VERSION ""

NS_ :

BS_:

BU_:

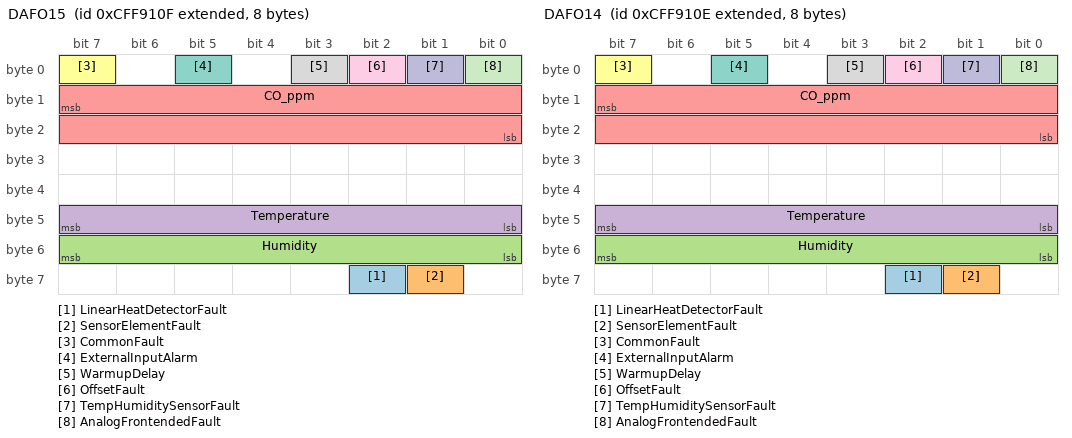
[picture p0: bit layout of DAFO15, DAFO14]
BO_ 2365559055 DAFO15: 8 Vector__XXX
 SG_ LinearHeatDetectorFault : 58|1@1+ (1,0) [0|0] "" Vector__XXX
 SG_ SensorElementFault : 57|1@1+ (1,0) [0|0] "" Vector__XXX
 SG_ Humidity : 48|8@1+ (1,0) [0|100] "" Vector__XXX
 SG_ Temperature : 40|8@1+ (1,0) [-40|125] "" Vector__XXX
 SG_ CO_ppm : 15|16@0+ (1,0) [0|0] "" Vector__XXX
 SG_ CommonFault : 7|1@1+ (1,0) [0|0] "" Vector__XXX
 SG_ ExternalInputAlarm : 5|1@1+ (1,0) [0|1] "" Vector__XXX
 SG_ WarmupDelay : 3|1@1+ (1,0) [0|0] "" Vector__XXX
 SG_ OffsetFault : 2|1@1+ (1,0) [0|0] "" Vector__XXX
 SG_ TempHumiditySensorFault : 1|1@1+ (1,0) [0|0] "" Vector__XXX
 SG_ AnalogFrontendedFault : 0|1@1+ (1,0) [0|1] "" Vector__XXX

BO_ 2365559054 DAFO14: 8 Vector__XXX
 SG_ LinearHeatDetectorFault : 58|1@1+ (1,0) [0|0] "" Vector__XXX
 SG_ SensorElementFault : 57|1@1+ (1,0) [0|0] "" Vector__XXX
 SG_ Humidity : 48|8@1+ (1,0) [0|100] "" Vector__XXX
 SG_ Temperature : 40|8@1+ (1,0) [-40|125] "" Vector__XXX
 SG_ CO_ppm : 15|16@0+ (1,0) [0|0] "" Vector__XXX
 SG_ CommonFault : 7|1@1+ (1,0) [0|0] "" Vector__XXX
 SG_ ExternalInputAlarm : 5|1@1+ (1,0) [0|1] "" Vector__XXX
 SG_ WarmupDelay : 3|1@1+ (1,0) [0|0] "" Vector__XXX
 SG_ OffsetFault : 2|1@1+ (1,0) [0|0] "" Vector__XXX
 SG_ TempHumiditySensorFault : 1|1@1+ (1,0) [0|0] "" Vector__XXX
 SG_ AnalogFrontendedFault : 0|1@1+ (1,0) [0|1] "" Vector__XXX

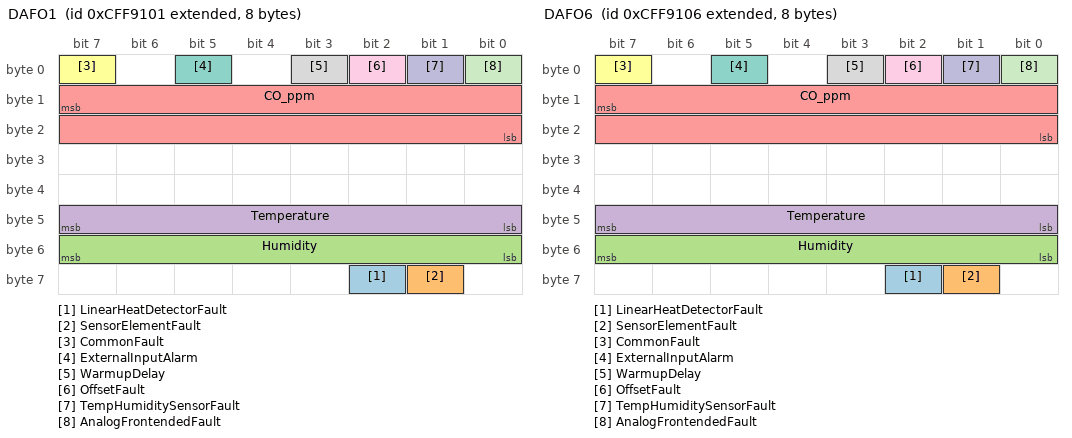
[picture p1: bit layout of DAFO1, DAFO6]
BO_ 2365559041 DAFO1: 8 Vector__XXX
 SG_ LinearHeatDetectorFault : 58|1@1+ (1,0) [0|0] "" Vector__XXX
 SG_ SensorElementFault : 57|1@1+ (1,0) [0|0] "" Vector__XXX
 SG_ Humidity : 48|8@1+ (1,0) [0|100] "" Vector__XXX
 SG_ Temperature : 40|8@1+ (1,0) [-40|125] "" Vector__XXX
 SG_ CO_ppm : 15|16@0+ (1,0) [0|0] "" Vector__XXX
 SG_ CommonFault : 7|1@1+ (1,0) [0|0] "" Vector__XXX
 SG_ ExternalInputAlarm : 5|1@1+ (1,0) [0|1] "" Vector__XXX
 SG_ WarmupDelay : 3|1@1+ (1,0) [0|0] "" Vector__XXX
 SG_ OffsetFault : 2|1@1+ (1,0) [0|0] "" Vector__XXX
 SG_ TempHumiditySensorFault : 1|1@1+ (1,0) [0|0] "" Vector__XXX
 SG_ AnalogFrontendedFault : 0|1@1+ (1,0) [0|1] "" Vector__XXX

BO_ 2365559046 DAFO6: 8 Vector__XXX
 SG_ LinearHeatDetectorFault : 58|1@1+ (1,0) [0|0] "" Vector__XXX
 SG_ SensorElementFault : 57|1@1+ (1,0) [0|0] "" Vector__XXX
 SG_ Humidity : 48|8@1+ (1,0) [0|100] "" Vector__XXX
 SG_ Temperature : 40|8@1+ (1,0) [-40|125] "" Vector__XXX
 SG_ CO_ppm : 15|16@0+ (1,0) [0|0] "" Vector__XXX
 SG_ CommonFault : 7|1@1+ (1,0) [0|0] "" Vector__XXX
 SG_ ExternalInputAlarm : 5|1@1+ (1,0) [0|1] "" Vector__XXX
 SG_ WarmupDelay : 3|1@1+ (1,0) [0|0] "" Vector__XXX
 SG_ OffsetFault : 2|1@1+ (1,0) [0|0] "" Vector__XXX
 SG_ TempHumiditySensorFault : 1|1@1+ (1,0) [0|0] "" Vector__XXX
 SG_ AnalogFrontendedFault : 0|1@1+ (1,0) [0|1] "" Vector__XXX

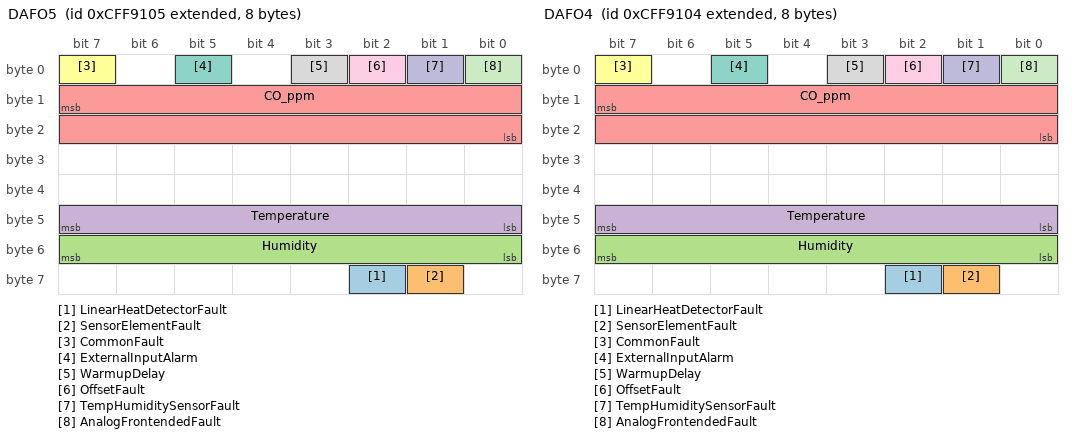
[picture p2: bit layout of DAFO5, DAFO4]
BO_ 2365559045 DAFO5: 8 Vector__XXX
 SG_ LinearHeatDetectorFault : 58|1@1+ (1,0) [0|0] "" Vector__XXX
 SG_ SensorElementFault : 57|1@1+ (1,0) [0|0] "" Vector__XXX
 SG_ Humidity : 48|8@1+ (1,0) [0|100] "" Vector__XXX
 SG_ Temperature : 40|8@1+ (1,0) [-40|125] "" Vector__XXX
 SG_ CO_ppm : 15|16@0+ (1,0) [0|0] "" Vector__XXX
 SG_ CommonFault : 7|1@1+ (1,0) [0|0] "" Vector__XXX
 SG_ ExternalInputAlarm : 5|1@1+ (1,0) [0|1] "" Vector__XXX
 SG_ WarmupDelay : 3|1@1+ (1,0) [0|0] "" Vector__XXX
 SG_ OffsetFault : 2|1@1+ (1,0) [0|0] "" Vector__XXX
 SG_ TempHumiditySensorFault : 1|1@1+ (1,0) [0|0] "" Vector__XXX
 SG_ AnalogFrontendedFault : 0|1@1+ (1,0) [0|1] "" Vector__XXX

BO_ 2365559044 DAFO4: 8 Vector__XXX
 SG_ LinearHeatDetectorFault : 58|1@1+ (1,0) [0|0] "" Vector__XXX
 SG_ SensorElementFault : 57|1@1+ (1,0) [0|0] "" Vector__XXX
 SG_ Humidity : 48|8@1+ (1,0) [0|100] "" Vector__XXX
 SG_ Temperature : 40|8@1+ (1,0) [-40|125] "" Vector__XXX
 SG_ CO_ppm : 15|16@0+ (1,0) [0|0] "" Vector__XXX
 SG_ CommonFault : 7|1@1+ (1,0) [0|0] "" Vector__XXX
 SG_ ExternalInputAlarm : 5|1@1+ (1,0) [0|1] "" Vector__XXX
 SG_ WarmupDelay : 3|1@1+ (1,0) [0|0] "" Vector__XXX
 SG_ OffsetFault : 2|1@1+ (1,0) [0|0] "" Vector__XXX
 SG_ TempHumiditySensorFault : 1|1@1+ (1,0) [0|0] "" Vector__XXX
 SG_ AnalogFrontendedFault : 0|1@1+ (1,0) [0|1] "" Vector__XXX

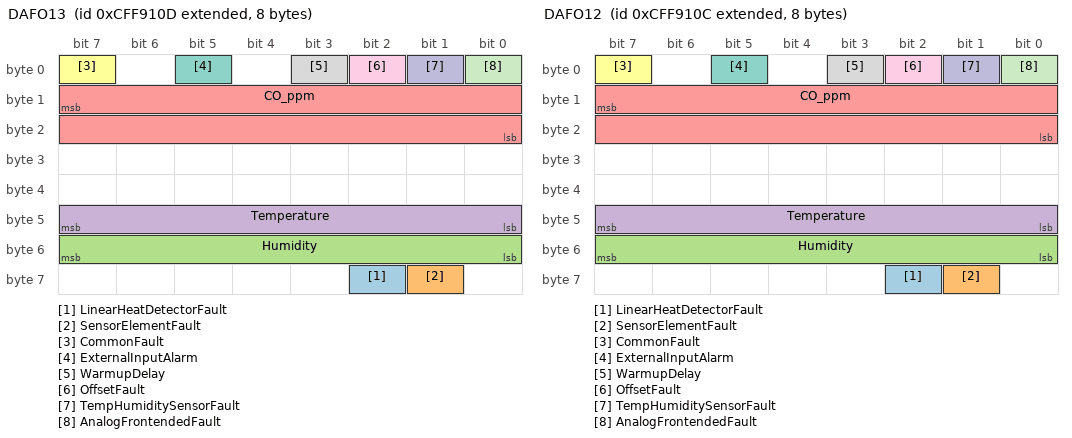
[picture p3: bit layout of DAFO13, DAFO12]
BO_ 2365559053 DAFO13: 8 Vector__XXX
 SG_ LinearHeatDetectorFault : 58|1@1+ (1,0) [0|0] "" Vector__XXX
 SG_ SensorElementFault : 57|1@1+ (1,0) [0|0] "" Vector__XXX
 SG_ Humidity : 48|8@1+ (1,0) [0|100] "" Vector__XXX
 SG_ Temperature : 40|8@1+ (1,0) [-40|125] "" Vector__XXX
 SG_ CO_ppm : 15|16@0+ (1,0) [0|0] "" Vector__XXX
 SG_ CommonFault : 7|1@1+ (1,0) [0|0] "" Vector__XXX
 SG_ ExternalInputAlarm : 5|1@1+ (1,0) [0|1] "" Vector__XXX
 SG_ WarmupDelay : 3|1@1+ (1,0) [0|0] "" Vector__XXX
 SG_ OffsetFault : 2|1@1+ (1,0) [0|0] "" Vector__XXX
 SG_ TempHumiditySensorFault : 1|1@1+ (1,0) [0|0] "" Vector__XXX
 SG_ AnalogFrontendedFault : 0|1@1+ (1,0) [0|1] "" Vector__XXX

BO_ 2365559052 DAFO12: 8 Vector__XXX
 SG_ LinearHeatDetectorFault : 58|1@1+ (1,0) [0|0] "" Vector__XXX
 SG_ SensorElementFault : 57|1@1+ (1,0) [0|0] "" Vector__XXX
 SG_ Humidity : 48|8@1+ (1,0) [0|100] "" Vector__XXX
 SG_ Temperature : 40|8@1+ (1,0) [-40|125] "" Vector__XXX
 SG_ CO_ppm : 15|16@0+ (1,0) [0|0] "" Vector__XXX
 SG_ CommonFault : 7|1@1+ (1,0) [0|0] "" Vector__XXX
 SG_ ExternalInputAlarm : 5|1@1+ (1,0) [0|1] "" Vector__XXX
 SG_ WarmupDelay : 3|1@1+ (1,0) [0|0] "" Vector__XXX
 SG_ OffsetFault : 2|1@1+ (1,0) [0|0] "" Vector__XXX
 SG_ TempHumiditySensorFault : 1|1@1+ (1,0) [0|0] "" Vector__XXX
 SG_ AnalogFrontendedFault : 0|1@1+ (1,0) [0|1] "" Vector__XXX

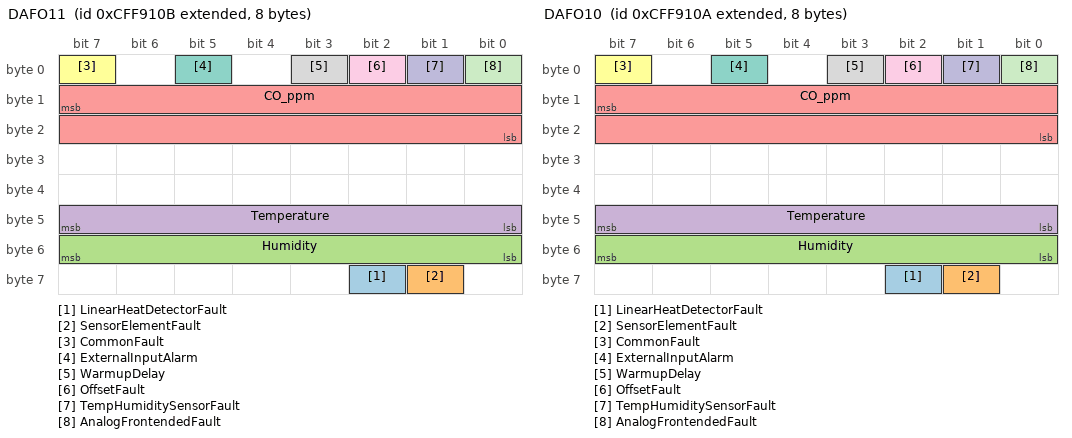
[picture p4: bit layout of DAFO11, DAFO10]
BO_ 2365559051 DAFO11: 8 Vector__XXX
 SG_ LinearHeatDetectorFault : 58|1@1+ (1,0) [0|0] "" Vector__XXX
 SG_ SensorElementFault : 57|1@1+ (1,0) [0|0] "" Vector__XXX
 SG_ Humidity : 48|8@1+ (1,0) [0|100] "" Vector__XXX
 SG_ Temperature : 40|8@1+ (1,0) [-40|125] "" Vector__XXX
 SG_ CO_ppm : 15|16@0+ (1,0) [0|0] "" Vector__XXX
 SG_ CommonFault : 7|1@1+ (1,0) [0|0] "" Vector__XXX
 SG_ ExternalInputAlarm : 5|1@1+ (1,0) [0|1] "" Vector__XXX
 SG_ WarmupDelay : 3|1@1+ (1,0) [0|0] "" Vector__XXX
 SG_ OffsetFault : 2|1@1+ (1,0) [0|0] "" Vector__XXX
 SG_ TempHumiditySensorFault : 1|1@1+ (1,0) [0|0] "" Vector__XXX
 SG_ AnalogFrontendedFault : 0|1@1+ (1,0) [0|1] "" Vector__XXX

BO_ 2365559050 DAFO10: 8 Vector__XXX
 SG_ LinearHeatDetectorFault : 58|1@1+ (1,0) [0|0] "" Vector__XXX
 SG_ SensorElementFault : 57|1@1+ (1,0) [0|0] "" Vector__XXX
 SG_ Humidity : 48|8@1+ (1,0) [0|100] "" Vector__XXX
 SG_ Temperature : 40|8@1+ (1,0) [-40|125] "" Vector__XXX
 SG_ CO_ppm : 15|16@0+ (1,0) [0|0] "" Vector__XXX
 SG_ CommonFault : 7|1@1+ (1,0) [0|0] "" Vector__XXX
 SG_ ExternalInputAlarm : 5|1@1+ (1,0) [0|1] "" Vector__XXX
 SG_ WarmupDelay : 3|1@1+ (1,0) [0|0] "" Vector__XXX
 SG_ OffsetFault : 2|1@1+ (1,0) [0|0] "" Vector__XXX
 SG_ TempHumiditySensorFault : 1|1@1+ (1,0) [0|0] "" Vector__XXX
 SG_ AnalogFrontendedFault : 0|1@1+ (1,0) [0|1] "" Vector__XXX

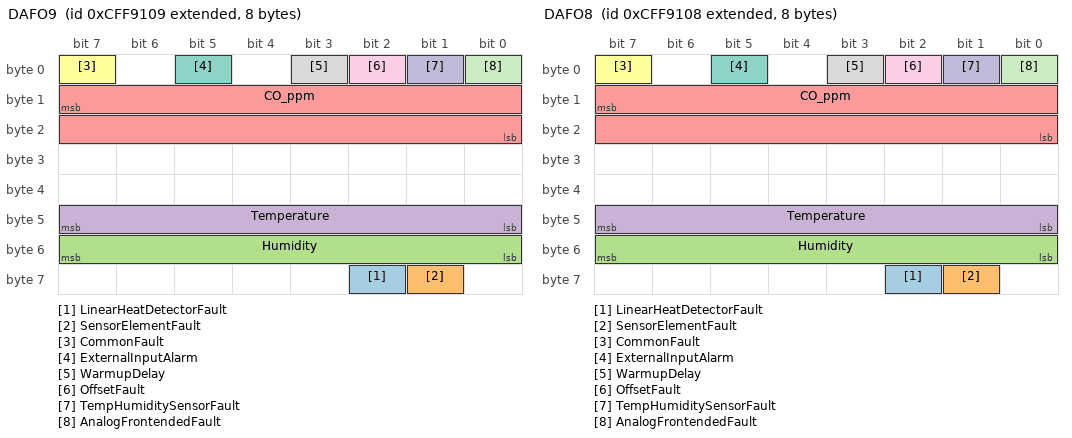
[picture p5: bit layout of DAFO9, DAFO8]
BO_ 2365559049 DAFO9: 8 Vector__XXX
 SG_ LinearHeatDetectorFault : 58|1@1+ (1,0) [0|0] "" Vector__XXX
 SG_ SensorElementFault : 57|1@1+ (1,0) [0|0] "" Vector__XXX
 SG_ Humidity : 48|8@1+ (1,0) [0|100] "" Vector__XXX
 SG_ Temperature : 40|8@1+ (1,0) [-40|125] "" Vector__XXX
 SG_ CO_ppm : 15|16@0+ (1,0) [0|0] "" Vector__XXX
 SG_ CommonFault : 7|1@1+ (1,0) [0|0] "" Vector__XXX
 SG_ ExternalInputAlarm : 5|1@1+ (1,0) [0|1] "" Vector__XXX
 SG_ WarmupDelay : 3|1@1+ (1,0) [0|0] "" Vector__XXX
 SG_ OffsetFault : 2|1@1+ (1,0) [0|0] "" Vector__XXX
 SG_ TempHumiditySensorFault : 1|1@1+ (1,0) [0|0] "" Vector__XXX
 SG_ AnalogFrontendedFault : 0|1@1+ (1,0) [0|1] "" Vector__XXX

BO_ 2365559048 DAFO8: 8 Vector__XXX
 SG_ LinearHeatDetectorFault : 58|1@1+ (1,0) [0|0] "" Vector__XXX
 SG_ SensorElementFault : 57|1@1+ (1,0) [0|0] "" Vector__XXX
 SG_ Humidity : 48|8@1+ (1,0) [0|100] "" Vector__XXX
 SG_ Temperature : 40|8@1+ (1,0) [-40|125] "" Vector__XXX
 SG_ CO_ppm : 15|16@0+ (1,0) [0|0] "" Vector__XXX
 SG_ CommonFault : 7|1@1+ (1,0) [0|0] "" Vector__XXX
 SG_ ExternalInputAlarm : 5|1@1+ (1,0) [0|1] "" Vector__XXX
 SG_ WarmupDelay : 3|1@1+ (1,0) [0|0] "" Vector__XXX
 SG_ OffsetFault : 2|1@1+ (1,0) [0|0] "" Vector__XXX
 SG_ TempHumiditySensorFault : 1|1@1+ (1,0) [0|0] "" Vector__XXX
 SG_ AnalogFrontendedFault : 0|1@1+ (1,0) [0|1] "" Vector__XXX

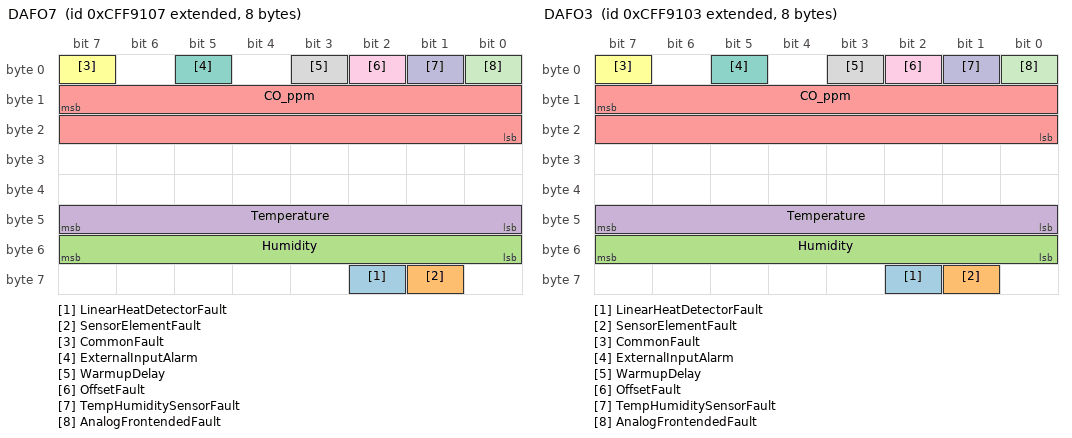
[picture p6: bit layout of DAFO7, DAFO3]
BO_ 2365559047 DAFO7: 8 Vector__XXX
 SG_ LinearHeatDetectorFault : 58|1@1+ (1,0) [0|0] "" Vector__XXX
 SG_ SensorElementFault : 57|1@1+ (1,0) [0|0] "" Vector__XXX
 SG_ Humidity : 48|8@1+ (1,0) [0|100] "" Vector__XXX
 SG_ Temperature : 40|8@1+ (1,0) [-40|125] "" Vector__XXX
 SG_ CO_ppm : 15|16@0+ (1,0) [0|0] "" Vector__XXX
 SG_ CommonFault : 7|1@1+ (1,0) [0|0] "" Vector__XXX
 SG_ ExternalInputAlarm : 5|1@1+ (1,0) [0|1] "" Vector__XXX
 SG_ WarmupDelay : 3|1@1+ (1,0) [0|0] "" Vector__XXX
 SG_ OffsetFault : 2|1@1+ (1,0) [0|0] "" Vector__XXX
 SG_ TempHumiditySensorFault : 1|1@1+ (1,0) [0|0] "" Vector__XXX
 SG_ AnalogFrontendedFault : 0|1@1+ (1,0) [0|1] "" Vector__XXX

BO_ 2365559043 DAFO3: 8 Vector__XXX
 SG_ LinearHeatDetectorFault : 58|1@1+ (1,0) [0|0] "" Vector__XXX
 SG_ SensorElementFault : 57|1@1+ (1,0) [0|0] "" Vector__XXX
 SG_ Humidity : 48|8@1+ (1,0) [0|100] "" Vector__XXX
 SG_ Temperature : 40|8@1+ (1,0) [-40|125] "" Vector__XXX
 SG_ CO_ppm : 15|16@0+ (1,0) [0|0] "" Vector__XXX
 SG_ CommonFault : 7|1@1+ (1,0) [0|0] "" Vector__XXX
 SG_ ExternalInputAlarm : 5|1@1+ (1,0) [0|1] "" Vector__XXX
 SG_ WarmupDelay : 3|1@1+ (1,0) [0|0] "" Vector__XXX
 SG_ OffsetFault : 2|1@1+ (1,0) [0|0] "" Vector__XXX
 SG_ TempHumiditySensorFault : 1|1@1+ (1,0) [0|0] "" Vector__XXX
 SG_ AnalogFrontendedFault : 0|1@1+ (1,0) [0|1] "" Vector__XXX

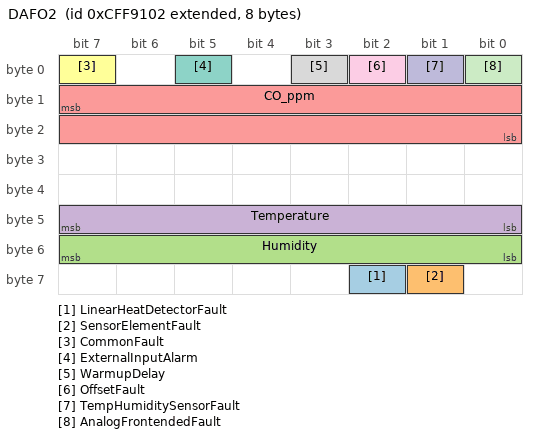
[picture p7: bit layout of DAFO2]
BO_ 2365559042 DAFO2: 8 Vector__XXX
 SG_ LinearHeatDetectorFault : 58|1@1+ (1,0) [0|0] "" Vector__XXX
 SG_ SensorElementFault : 57|1@1+ (1,0) [0|0] "" Vector__XXX
 SG_ Humidity : 48|8@1+ (1,0) [0|100] "" Vector__XXX
 SG_ Temperature : 40|8@1+ (1,0) [-40|125] "" Vector__XXX
 SG_ CO_ppm : 15|16@0+ (1,0) [0|0] "" Vector__XXX
 SG_ CommonFault : 7|1@1+ (1,0) [0|0] "" Vector__XXX
 SG_ ExternalInputAlarm : 5|1@1+ (1,0) [0|1] "" Vector__XXX
 SG_ WarmupDelay : 3|1@1+ (1,0) [0|0] "" Vector__XXX
 SG_ OffsetFault : 2|1@1+ (1,0) [0|0] "" Vector__XXX
 SG_ TempHumiditySensorFault : 1|1@1+ (1,0) [0|0] "" Vector__XXX
 SG_ AnalogFrontendedFault : 0|1@1+ (1,0) [0|1] "" Vector__XXX

CM_ SG_ 2365559055 LinearHeatDetectorFault "Available if linear heat detector is available on the sensor";
CM_ SG_ 2365559055 SensorElementFault "Sensor element or full sensor needs to be replaced";
CM_ SG_ 2365559055 CO_ppm "CO reading 0-1000ppm";
CM_ SG_ 2365559055 CommonFault "Generic fault bit of the sensor";
CM_ SG_ 2365559055 ExternalInputAlarm "Connected linear heat detector (or manual release) have created alarm condition.";
CM_ SG_ 2365559055 WarmupDelay "Indicates that sensor is not fully started yet and is therefore not functional.";
CM_ SG_ 2365559055 OffsetFault "Fault calculating CO measurement. Cycle power off for 1 hour and retry.";
CM_ SG_ 2365559055 TempHumiditySensorFault "Fault in temperature and humidity sensor";
CM_ SG_ 2365559055 AnalogFrontendedFault "Fault in analog electronics";
CM_ SG_ 2365559054 LinearHeatDetectorFault "Available if linear heat detector is available on the sensor";
CM_ SG_ 2365559054 SensorElementFault "Sensor element or full sensor needs to be replaced";
CM_ SG_ 2365559054 CO_ppm "CO reading 0-1000ppm";
CM_ SG_ 2365559054 CommonFault "Generic fault bit of the sensor";
CM_ SG_ 2365559054 ExternalInputAlarm "Connected linear heat detector (or manual release) have created alarm condition.";
CM_ SG_ 2365559054 WarmupDelay "Indicates that sensor is not fully started yet and is therefore not functional.";
CM_ SG_ 2365559054 OffsetFault "Fault calculating CO measurement. Cycle power off for 1 hour and retry.";
CM_ SG_ 2365559054 TempHumiditySensorFault "Fault in temperature and humidity sensor";
CM_ SG_ 2365559054 AnalogFrontendedFault "Fault in analog electronics";
CM_ SG_ 2365559041 LinearHeatDetectorFault "Available if linear heat detector is available on the sensor";
CM_ SG_ 2365559041 SensorElementFault "Sensor element or full sensor needs to be replaced";
CM_ SG_ 2365559041 CO_ppm "CO reading 0-1000ppm";
CM_ SG_ 2365559041 CommonFault "Generic fault bit of the sensor";
CM_ SG_ 2365559041 ExternalInputAlarm "Connected linear heat detector (or manual release) have created alarm condition.";
CM_ SG_ 2365559041 WarmupDelay "Indicates that sensor is not fully started yet and is therefore not functional.";
CM_ SG_ 2365559041 OffsetFault "Fault calculating CO measurement. Cycle power off for 1 hour and retry.";
CM_ SG_ 2365559041 TempHumiditySensorFault "Fault in temperature and humidity sensor";
CM_ SG_ 2365559041 AnalogFrontendedFault "Fault in analog electronics";
CM_ SG_ 2365559046 LinearHeatDetectorFault "Available if linear heat detector is available on the sensor";
CM_ SG_ 2365559046 SensorElementFault "Sensor element or full sensor needs to be replaced";
CM_ SG_ 2365559046 CO_ppm "CO reading 0-1000ppm";
CM_ SG_ 2365559046 CommonFault "Generic fault bit of the sensor";
CM_ SG_ 2365559046 ExternalInputAlarm "Connected linear heat detector (or manual release) have created alarm condition.";
CM_ SG_ 2365559046 WarmupDelay "Indicates that sensor is not fully started yet and is therefore not functional.";
CM_ SG_ 2365559046 OffsetFault "Fault calculating CO measurement. Cycle power off for 1 hour and retry.";
CM_ SG_ 2365559046 TempHumiditySensorFault "Fault in temperature and humidity sensor";
CM_ SG_ 2365559046 AnalogFrontendedFault "Fault in analog electronics";
CM_ SG_ 2365559045 LinearHeatDetectorFault "Available if linear heat detector is available on the sensor";
CM_ SG_ 2365559045 SensorElementFault "Sensor element or full sensor needs to be replaced";
CM_ SG_ 2365559045 CO_ppm "CO reading 0-1000ppm";
CM_ SG_ 2365559045 CommonFault "Generic fault bit of the sensor";
CM_ SG_ 2365559045 ExternalInputAlarm "Connected linear heat detector (or manual release) have created alarm condition.";
CM_ SG_ 2365559045 WarmupDelay "Indicates that sensor is not fully started yet and is therefore not functional.";
CM_ SG_ 2365559045 OffsetFault "Fault calculating CO measurement. Cycle power off for 1 hour and retry.";
CM_ SG_ 2365559045 TempHumiditySensorFault "Fault in temperature and humidity sensor";
CM_ SG_ 2365559045 AnalogFrontendedFault "Fault in analog electronics";
CM_ SG_ 2365559044 LinearHeatDetectorFault "Available if linear heat detector is available on the sensor";
CM_ SG_ 2365559044 SensorElementFault "Sensor element or full sensor needs to be replaced";
CM_ SG_ 2365559044 CO_ppm "CO reading 0-1000ppm";
CM_ SG_ 2365559044 CommonFault "Generic fault bit of the sensor";
CM_ SG_ 2365559044 ExternalInputAlarm "Connected linear heat detector (or manual release) have created alarm condition.";
CM_ SG_ 2365559044 WarmupDelay "Indicates that sensor is not fully started yet and is therefore not functional.";
CM_ SG_ 2365559044 OffsetFault "Fault calculating CO measurement. Cycle power off for 1 hour and retry.";
CM_ SG_ 2365559044 TempHumiditySensorFault "Fault in temperature and humidity sensor";
CM_ SG_ 2365559044 AnalogFrontendedFault "Fault in analog electronics";
CM_ SG_ 2365559053 LinearHeatDetectorFault "Available if linear heat detector is available on the sensor";
CM_ SG_ 2365559053 SensorElementFault "Sensor element or full sensor needs to be replaced";
CM_ SG_ 2365559053 CO_ppm "CO reading 0-1000ppm";
CM_ SG_ 2365559053 CommonFault "Generic fault bit of the sensor";
CM_ SG_ 2365559053 ExternalInputAlarm "Connected linear heat detector (or manual release) have created alarm condition.";
CM_ SG_ 2365559053 WarmupDelay "Indicates that sensor is not fully started yet and is therefore not functional.";
CM_ SG_ 2365559053 OffsetFault "Fault calculating CO measurement. Cycle power off for 1 hour and retry.";
CM_ SG_ 2365559053 TempHumiditySensorFault "Fault in temperature and humidity sensor";
CM_ SG_ 2365559053 AnalogFrontendedFault "Fault in analog electronics";
CM_ SG_ 2365559052 LinearHeatDetectorFault "Available if linear heat detector is available on the sensor";
CM_ SG_ 2365559052 SensorElementFault "Sensor element or full sensor needs to be replaced";
CM_ SG_ 2365559052 CO_ppm "CO reading 0-1000ppm";
CM_ SG_ 2365559052 CommonFault "Generic fault bit of the sensor";
CM_ SG_ 2365559052 ExternalInputAlarm "Connected linear heat detector (or manual release) have created alarm condition.";
CM_ SG_ 2365559052 WarmupDelay "Indicates that sensor is not fully started yet and is therefore not functional.";
CM_ SG_ 2365559052 OffsetFault "Fault calculating CO measurement. Cycle power off for 1 hour and retry.";
CM_ SG_ 2365559052 TempHumiditySensorFault "Fault in temperature and humidity sensor";
CM_ SG_ 2365559052 AnalogFrontendedFault "Fault in analog electronics";
CM_ SG_ 2365559051 LinearHeatDetectorFault "Available if linear heat detector is available on the sensor";
CM_ SG_ 2365559051 SensorElementFault "Sensor element or full sensor needs to be replaced";
CM_ SG_ 2365559051 CO_ppm "CO reading 0-1000ppm";
CM_ SG_ 2365559051 CommonFault "Generic fault bit of the sensor";
CM_ SG_ 2365559051 ExternalInputAlarm "Connected linear heat detector (or manual release) have created alarm condition.";
CM_ SG_ 2365559051 WarmupDelay "Indicates that sensor is not fully started yet and is therefore not functional.";
CM_ SG_ 2365559051 OffsetFault "Fault calculating CO measurement. Cycle power off for 1 hour and retry.";
CM_ SG_ 2365559051 TempHumiditySensorFault "Fault in temperature and humidity sensor";
CM_ SG_ 2365559051 AnalogFrontendedFault "Fault in analog electronics";
CM_ SG_ 2365559050 LinearHeatDetectorFault "Available if linear heat detector is available on the sensor";
CM_ SG_ 2365559050 SensorElementFault "Sensor element or full sensor needs to be replaced";
CM_ SG_ 2365559050 CO_ppm "CO reading 0-1000ppm";
CM_ SG_ 2365559050 CommonFault "Generic fault bit of the sensor";
CM_ SG_ 2365559050 ExternalInputAlarm "Connected linear heat detector (or manual release) have created alarm condition.";
CM_ SG_ 2365559050 WarmupDelay "Indicates that sensor is not fully started yet and is therefore not functional.";
CM_ SG_ 2365559050 OffsetFault "Fault calculating CO measurement. Cycle power off for 1 hour and retry.";
CM_ SG_ 2365559050 TempHumiditySensorFault "Fault in temperature and humidity sensor";
CM_ SG_ 2365559050 AnalogFrontendedFault "Fault in analog electronics";
CM_ SG_ 2365559049 LinearHeatDetectorFault "Available if linear heat detector is available on the sensor";
CM_ SG_ 2365559049 SensorElementFault "Sensor element or full sensor needs to be replaced";
CM_ SG_ 2365559049 CO_ppm "CO reading 0-1000ppm";
CM_ SG_ 2365559049 CommonFault "Generic fault bit of the sensor";
CM_ SG_ 2365559049 ExternalInputAlarm "Connected linear heat detector (or manual release) have created alarm condition.";
CM_ SG_ 2365559049 WarmupDelay "Indicates that sensor is not fully started yet and is therefore not functional.";
CM_ SG_ 2365559049 OffsetFault "Fault calculating CO measurement. Cycle power off for 1 hour and retry.";
CM_ SG_ 2365559049 TempHumiditySensorFault "Fault in temperature and humidity sensor";
CM_ SG_ 2365559049 AnalogFrontendedFault "Fault in analog electronics";
CM_ SG_ 2365559048 LinearHeatDetectorFault "Available if linear heat detector is available on the sensor";
CM_ SG_ 2365559048 SensorElementFault "Sensor element or full sensor needs to be replaced";
CM_ SG_ 2365559048 CO_ppm "CO reading 0-1000ppm";
CM_ SG_ 2365559048 CommonFault "Generic fault bit of the sensor";
CM_ SG_ 2365559048 ExternalInputAlarm "Connected linear heat detector (or manual release) have created alarm condition.";
CM_ SG_ 2365559048 WarmupDelay "Indicates that sensor is not fully started yet and is therefore not functional.";
CM_ SG_ 2365559048 OffsetFault "Fault calculating CO measurement. Cycle power off for 1 hour and retry.";
CM_ SG_ 2365559048 TempHumiditySensorFault "Fault in temperature and humidity sensor";
CM_ SG_ 2365559048 AnalogFrontendedFault "Fault in analog electronics";
CM_ SG_ 2365559047 LinearHeatDetectorFault "Available if linear heat detector is available on the sensor";
CM_ SG_ 2365559047 SensorElementFault "Sensor element or full sensor needs to be replaced";
CM_ SG_ 2365559047 CO_ppm "CO reading 0-1000ppm";
CM_ SG_ 2365559047 CommonFault "Generic fault bit of the sensor";
CM_ SG_ 2365559047 ExternalInputAlarm "Connected linear heat detector (or manual release) have created alarm condition.";
CM_ SG_ 2365559047 WarmupDelay "Indicates that sensor is not fully started yet and is therefore not functional.";
CM_ SG_ 2365559047 OffsetFault "Fault calculating CO measurement. Cycle power off for 1 hour and retry.";
CM_ SG_ 2365559047 TempHumiditySensorFault "Fault in temperature and humidity sensor";
CM_ SG_ 2365559047 AnalogFrontendedFault "Fault in analog electronics";
CM_ SG_ 2365559043 LinearHeatDetectorFault "Available if linear heat detector is available on the sensor";
CM_ SG_ 2365559043 SensorElementFault "Sensor element or full sensor needs to be replaced";
CM_ SG_ 2365559043 CO_ppm "CO reading 0-1000ppm";
CM_ SG_ 2365559043 CommonFault "Generic fault bit of the sensor";
CM_ SG_ 2365559043 ExternalInputAlarm "Connected linear heat detector (or manual release) have created alarm condition.";
CM_ SG_ 2365559043 WarmupDelay "Indicates that sensor is not fully started yet and is therefore not functional.";
CM_ SG_ 2365559043 OffsetFault "Fault calculating CO measurement. Cycle power off for 1 hour and retry.";
CM_ SG_ 2365559043 TempHumiditySensorFault "Fault in temperature and humidity sensor";
CM_ SG_ 2365559043 AnalogFrontendedFault "Fault in analog electronics";
CM_ SG_ 2365559042 LinearHeatDetectorFault "Available if linear heat detector is available on the sensor";
CM_ SG_ 2365559042 SensorElementFault "Sensor element or full sensor needs to be replaced";
CM_ SG_ 2365559042 CO_ppm "CO reading 0-1000ppm";
CM_ SG_ 2365559042 CommonFault "Generic fault bit of the sensor";
CM_ SG_ 2365559042 ExternalInputAlarm "Connected linear heat detector (or manual release) have created alarm condition.";
CM_ SG_ 2365559042 WarmupDelay "Indicates that sensor is not fully started yet and is therefore not functional.";
CM_ SG_ 2365559042 OffsetFault "Fault calculating CO measurement. Cycle power off for 1 hour and retry.";
CM_ SG_ 2365559042 TempHumiditySensorFault "Fault in temperature and humidity sensor";
CM_ SG_ 2365559042 AnalogFrontendedFault "Fault in analog electronics";
BA_DEF_ SG_  "SigType" ENUM  "Default","Range","RangeSigned","ASCII","Discrete","Control","ReferencePGN","DTC","StringDelimiter","StringLength","StringLengthControl","MessageCounter","MessageChecksum";
BA_DEF_ SG_  "GenSigEVName" STRING ;
BA_DEF_ SG_  "GenSigILSupport" ENUM  "No","Yes";
BA_DEF_ SG_  "GenSigSendType" ENUM  "Cyclic","OnWrite","OnWriteWithRepetition","OnChange","OnChangeWithRepetition","IfActive","IfActiveWithRepetition","NoSigSendType";
BA_DEF_ BO_  "GenMsgILSupport" ENUM  "No","Yes";
BA_DEF_ BU_  "NmStationAddress" INT 0 255;
BA_DEF_ BO_  "GenMsgSendType" ENUM  "cyclic","NotUsed","IfActive","NotUsed","NotUsed","NotUsed","NotUsed","NotUsed","noMsgSendType";
BA_DEF_ BO_  "GenMsgRequestable" INT 0 1;
BA_DEF_  "DBName" STRING ;
BA_DEF_  "BusType" STRING ;
BA_DEF_  "ProtocolType" STRING ;
BA_DEF_ BO_  "VFrameFormat" ENUM  "StandardCAN","ExtendedCAN","reserved","J1939PG";
BA_DEF_DEF_  "SigType" "Default";
BA_DEF_DEF_  "GenSigEVName" "Env@Nodename_@Signame";
BA_DEF_DEF_  "GenSigILSupport" "Yes";
BA_DEF_DEF_  "GenSigSendType" "NoSigSendType";
BA_DEF_DEF_  "GenMsgILSupport" "Yes";
BA_DEF_DEF_  "NmStationAddress" 254;
BA_DEF_DEF_  "GenMsgSendType" "noMsgSendType";
BA_DEF_DEF_  "GenMsgRequestable" 1;
BA_DEF_DEF_  "DBName" "";
BA_DEF_DEF_  "BusType" "CAN";
BA_DEF_DEF_  "ProtocolType" "J1939";
BA_DEF_DEF_  "VFrameFormat" "J1939PG";
BA_ "DBName" "DAFO";
